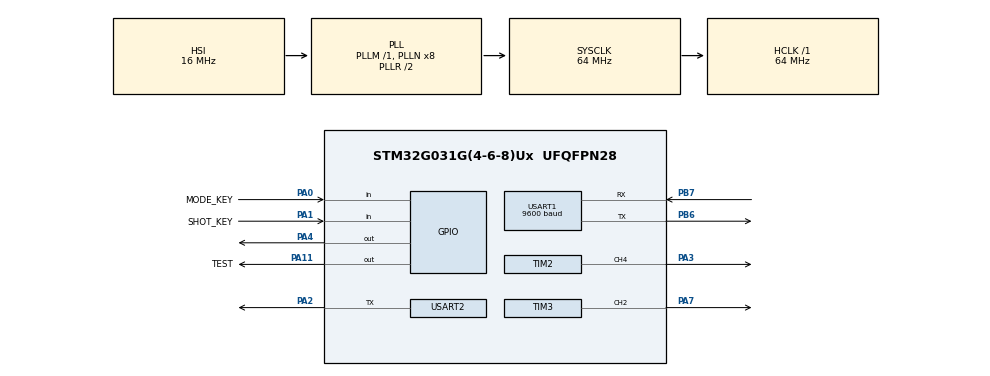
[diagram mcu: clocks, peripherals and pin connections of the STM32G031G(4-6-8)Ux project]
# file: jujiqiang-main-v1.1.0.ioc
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Mcu.Family=STM32G0
TIM2.Channel-PWM\ Generation4\ CH4=TIM_CHANNEL_4
RCC.CortexFreq_Value=64000000
PA11\ [PA9].GPIO_Label=TEST
USART1.BaudRate=9600
Dma.TIM2_CH4.0.Instance=DMA1_Channel1
PA3.GPIO_PuPd=GPIO_PULLUP
PA14-BOOT0.Mode=Serial_Wire
PA0.GPIO_Label=MODE_KEY
RCC.EXTERNAL_CLOCK_VALUE=12288000
Dma.TIM2_CH4.0.MemDataAlignment=DMA_MDATAALIGN_WORD
PA3.GPIO_Speed=GPIO_SPEED_FREQ_VERY_HIGH
Dma.TIM2_CH4.0.SyncEnable=DISABLE
USART2.BaudRate=9600
RCC.SYSCLKSource=RCC_SYSCLKSOURCE_PLLCLK
ProjectManager.StackSize=0x400
USART1.VirtualMode-Asynchronous=VM_ASYNC
PA13.Signal=SYS_SWDIO
ProjectManager.TargetToolchain=STM32CubeIDE
RCC.HCLKFreq_Value=64000000
TIM3.Period=19999
PB6.Signal=USART1_TX
Dma.TIM2_CH4.0.EventEnable=DISABLE
PA11\ [PA9].GPIO_PuPd=GPIO_PULLUP
PB6.Mode=Asynchronous
Dma.TIM2_CH4.0.Polarity=HAL_DMAMUX_REQ_GEN_RISING
RCC.LSE_VALUE=32768
PA1.GPIO_PuPd=GPIO_PULLUP
PA1.Signal=GPIO_Input
PA7.GPIO_PuPd=GPIO_PULLUP
RCC.AHBFreq_Value=64000000
PA14-BOOT0.Signal=SYS_SWCLK
SH.S_TIM3_CH2.0=TIM3_CH2,PWM Generation2 CH2
RCC.HSE_VALUE=8000000
PA4.GPIO_PuPd=GPIO_PULLUP
board=custom
Dma.TIM2_CH4.0.Priority=DMA_PRIORITY_LOW
RCC.VCOOutputFreq_Value=128000000
PA7.GPIO_Speed=GPIO_SPEED_FREQ_VERY_HIGH
Dma.TIM2_CH4.0.MemInc=DMA_MINC_ENABLE
Dma.TIM2_CH4.0.PeriphInc=DMA_PINC_DISABLE
VP_TIM2_VS_ClockSourceINT.Mode=Internal
TIM3.Prescaler=63
RCC.ADCFreq_Value=64000000
PA1.GPIO_Label=SHOT_KEY
PB7.Signal=USART1_RX
Dma.TIM2_CH4.0.SyncSignalID=NONE
TIM2.Period=79
PA13.Mode=Serial_Wire
Dma.TIM2_CH4.0.PeriphDataAlignment=DMA_PDATAALIGN_WORD
Mcu.Name=STM32G031G(4-6-8)Ux
PA11\ [PA9].Signal=GPIO_Output
PA2.Signal=USART2_TX
PA0.Signal=GPIO_Input
PA4.Signal=GPIO_Output
RCC.SYSCLKFreq_VALUE=64000000
Mcu.Package=UFQFPN28
Dma.TIM2_CH4.0.SyncPolarity=HAL_DMAMUX_SYNC_NO_EVENT
PA0.GPIO_PuPd=GPIO_PULLUP
USART2.VirtualMode-Half_duplex(single_wire_mode)=VM_ASYNC
PB7.Mode=Asynchronous
ProjectManager.HeapSize=0x200
Dma.TIM2_CH4.0.RequestNumber=1
SH.S_TIM2_CH4.0=TIM2_CH4,PWM Generation4 CH4
RCC.HSI_VALUE=16000000
Dma.TIM2_CH4.0.SyncRequestNumber=1
TIM3.Channel-PWM\ Generation2\ CH2=TIM_CHANNEL_2
PA2.Mode=Half_duplex(single_wire_mode)
TIM3.Pulse-PWM\ Generation2\ CH2=1000
NVIC.DMA1_Channel1_IRQn=true\:0\:0\:false\:false\:true\:false\:true
NVIC.USART1_IRQn=true\:0\:0\:false\:false\:true\:true\:true
Dma.Request0=TIM2_CH4
USART2.Mode=MODE_TX
Dma.TIM2_CH4.0.SignalID=NONE
PA3.Signal=S_TIM2_CH4
PA7.Signal=S_TIM3_CH2
Dma.TIM2_CH4.0.Mode=DMA_NORMAL
Dma.TIM2_CH4.0.Direction=DMA_MEMORY_TO_PERIPH

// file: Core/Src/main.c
/* USER CODE BEGIN Header */
/**
  ******************************************************************************
  * @file           : main.c
  * @brief          : Main program body
  ******************************************************************************
  * @attention
  *
  * <h2><center>&copy; Copyright (c) 2021 STMicroelectronics.
  * All rights reserved.</center></h2>
  *
  * This software component is licensed by ST under BSD 3-Clause license,
  * the "License"; You may not use this file except in compliance with the
  * License. You may obtain a copy of the License at:
  *                        opensource.org/licenses/BSD-3-Clause
  *
  ******************************************************************************
  */
/* USER CODE END Header */
#include "main.h"
#include "dma.h"
#include "tim.h"
#include "usart.h"
#include "gpio.h"

/* USER CODE BEGIN Includes */
#include "S1_main.h"
/* USER CODE END Includes */

void SystemClock_Config(void);

int main(void)
{

  /* MCU Configuration--------------------------------------------------------*/

  /* Reset of all peripherals, Initializes the Flash interface and the Systick. */
  HAL_Init();

  /* Configure the system clock */
  SystemClock_Config();

  /* Initialize all configured peripherals */
  MX_GPIO_Init();
  MX_DMA_Init();
  MX_TIM3_Init();
  MX_TIM2_Init();
  MX_USART2_UART_Init();
  MX_USART1_UART_Init();
  /* USER CODE BEGIN 2 */
  setup();
  /* USER CODE END 2 */

  /* Infinite loop */
  while (1)
  {

    /* USER CODE BEGIN 3 */
	  loop();
  }
  /* USER CODE END 3 */
}

void SystemClock_Config(void)
{
  RCC_OscInitTypeDef RCC_OscInitStruct = {0};
  RCC_ClkInitTypeDef RCC_ClkInitStruct = {0};
  RCC_PeriphCLKInitTypeDef PeriphClkInit = {0};

  /** Configure the main internal regulator output voltage
  */
  HAL_PWREx_ControlVoltageScaling(PWR_REGULATOR_VOLTAGE_SCALE1);
  /** Initializes the RCC Oscillators according to the specified parameters
  * in the RCC_OscInitTypeDef structure.
  */
  RCC_OscInitStruct.OscillatorType = RCC_OSCILLATORTYPE_HSI;
  RCC_OscInitStruct.HSIState = RCC_HSI_ON;
  RCC_OscInitStruct.HSIDiv = RCC_HSI_DIV1;
  RCC_OscInitStruct.HSICalibrationValue = RCC_HSICALIBRATION_DEFAULT;
  RCC_OscInitStruct.PLL.PLLState = RCC_PLL_ON;
  RCC_OscInitStruct.PLL.PLLSource = RCC_PLLSOURCE_HSI;
  RCC_OscInitStruct.PLL.PLLM = RCC_PLLM_DIV1;
  RCC_OscInitStruct.PLL.PLLN = 8;
  RCC_OscInitStruct.PLL.PLLP = RCC_PLLP_DIV2;
  RCC_OscInitStruct.PLL.PLLQ = RCC_PLLQ_DIV2;
  RCC_OscInitStruct.PLL.PLLR = RCC_PLLR_DIV2;
  if (HAL_RCC_OscConfig(&RCC_OscInitStruct) != HAL_OK)
  {
    Error_Handler();
  }
  /** Initializes the CPU, AHB and APB buses clocks
  */
  RCC_ClkInitStruct.ClockType = RCC_CLOCKTYPE_HCLK|RCC_CLOCKTYPE_SYSCLK
                              |RCC_CLOCKTYPE_PCLK1;
  RCC_ClkInitStruct.SYSCLKSource = RCC_SYSCLKSOURCE_PLLCLK;
  RCC_ClkInitStruct.AHBCLKDivider = RCC_SYSCLK_DIV1;
  RCC_ClkInitStruct.APB1CLKDivider = RCC_HCLK_DIV1;

  if (HAL_RCC_ClockConfig(&RCC_ClkInitStruct, FLASH_LATENCY_2) != HAL_OK)
  {
    Error_Handler();
  }
  /** Initializes the peripherals clocks
  */
  PeriphClkInit.PeriphClockSelection = RCC_PERIPHCLK_USART1;
  PeriphClkInit.Usart1ClockSelection = RCC_USART1CLKSOURCE_PCLK1;
  if (HAL_RCCEx_PeriphCLKConfig(&PeriphClkInit) != HAL_OK)
  {
    Error_Handler();
  }
}

void Error_Handler(void)
{
  __disable_irq();
  while (1)
  {
  }
}

/************************ (C) COPYRIGHT STMicroelectronics *****END OF FILE****/
